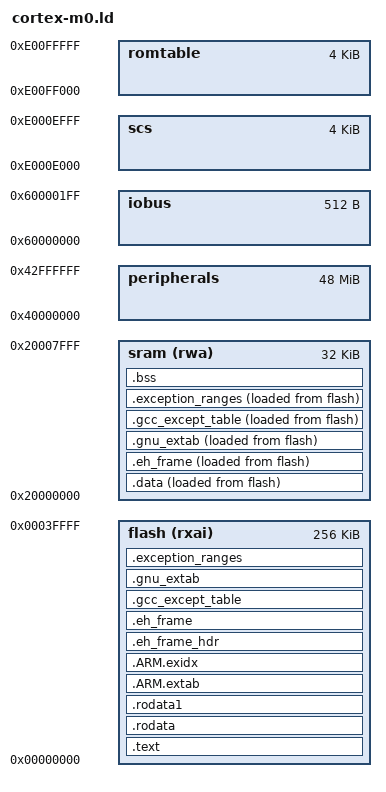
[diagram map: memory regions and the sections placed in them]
MEMORY {
	flash   (rxai)  : org = 0x00000000, len = 0x00040000
	sram    (rwa)   : org = 0x20000000, len = 0x00008000
	peripherals     : org = 0x40000000, len = 0x03000000
	iobus           : org = 0x60000000, len = 0x00000200
	scs             : org = 0xe000e000, len = 0x00001000
	romtable        : org = 0xe00ff000, len = 0x00001000
}

SECTIONS {  
  .text : {
    ___image_lma = LOADADDR(.text);
    *(.header)
    *(.header.*)
    *(.text)
    *(.text.*)
  } >flash AT >flash

  .rodata : {
    *(.rodata .rodata.* .gnu.linkonce.r.*)

    . = ALIGN(4);
    PROVIDE_HIDDEN(__init_array_st = .);
    KEEP(*(SORT_BY_INIT_PRIORITY(.init_array)));
    KEEP(*(SORT_BY_INIT_PRIORITY(.init_array.*)));
    KEEP(*(SORT_BY_INIT_PRIORITY(.ctors.*)));
    PROVIDE_HIDDEN(__init_array_en = .);
    PROVIDE_HIDDEN(__fini_array_st = .);
    KEEP(*(SORT_BY_INIT_PRIORITY(.fini_array)));
    KEEP(*(SORT_BY_INIT_PRIORITY(.fini_array.*)));
    KEEP(*(SORT_BY_INIT_PRIORITY(.dtors.*)));
    PROVIDE_HIDDEN(__fini_array_en = .);
  } >flash AT >flash

  .rodata1 : {
    *(.rodata1)
  } >flash AT >flash

  .ARM.extab : {
    *(.ARM.extab* .gnu.linkonce.armextab.*)
  } >flash AT >flash
  PROVIDE_HIDDEN (__exidx_start = .);
  .ARM.exidx : {
    *(.ARM.exidx* .gnu.linkonce.armexidx.*)
  } >flash AT >flash
   PROVIDE_HIDDEN (__exidx_end = .);
  .eh_frame_hdr : {
    *(.eh_frame_hdr) *(.eh_frame_entry .eh_frame_entry.*)
  } >flash AT >flash
  .eh_frame : ONLY_IF_RO {
    KEEP (*(.eh_frame)) 
    *(.eh_frame.*)
  } >flash AT >flash
  .gcc_except_table : ONLY_IF_RO {
    *(.gcc_except_table .gcc_except_table.*)
  } >flash AT >flash
  .gnu_extab : ONLY_IF_RO {
    *(.gnu_extab*)
  } >flash AT >flash
  /* These sections are generated by the Sun/Oracle C++ compiler.  */
  .exception_ranges : ONLY_IF_RO {
    *(.exception_ranges .exception_ranges*)
  } >flash AT >flash


  /* sram */

  .data : {
    __image_data_st_lma = LOADADDR(.data);
    __image_data_st_vma = ABSOLUTE(.);

    *(.data)
    *(.data.*)
    
    __image_data_en_vma = ABSOLUTE(.);    
  } >sram AT >flash

  /* Adjust the address for the data segment.  We want to adjust up to
     the same address within the page on the next page up.  
  . = ALIGN(CONSTANT (MAXPAGESIZE)) + (. & (CONSTANT (MAXPAGESIZE) - 1));
  */
  /* Exception handling  */
  .eh_frame       : ONLY_IF_RW {
    KEEP (*(.eh_frame)) *(.eh_frame.*)
  } >sram AT >flash
  .gnu_extab      : ONLY_IF_RW {
    *(.gnu_extab)
  } >sram AT >flash
  .gcc_except_table : ONLY_IF_RW {
    *(.gcc_except_table .gcc_except_table.*)
  } >sram AT >flash
  .exception_ranges : ONLY_IF_RW {
    *(.exception_ranges .exception_ranges*)
  } >sram AT >flash

  .bss (NOLOAD) : {
    __image_bss_st = ABSOLUTE(.);
    *(.bss)
    *(.bss.*)
    __image_bss_en = ABSOLUTE(.);
  } >sram

  /* fixme, 8000 */
  __end_of_ram = ABSOLUTE(0x20004000);
}
